# CY8C5888AXI_LP096 register map
File version: 0.1
CY8C58LP
Registers are 8-bit, read-write, no defined reset value unless marked. A register's access mark holds for its fields unless they carry their own. Offsets are from the block's base; lines under a group give offsets from that group; [hi:lo] are bit positions; {n}, {i} and the like mark numbered series; 'fields as' and 'values as' point back to an identical list; <NAME> marks a mode.

## Memory map
0x00000000 EN_B_PWM
0x00000000 EN_A_PWM
0x4000647D Motor_B
0x4000647F Motor_A

## Motor_B
Base 0x4000647D
0x00 Motor_B_CONTROL_REG

## EN_B_PWM
Base 0x00000000
0x4000642C EN_B_PWM_COMPARE_Reg 16-bit — UDB.D0 - Assigned Compare Value
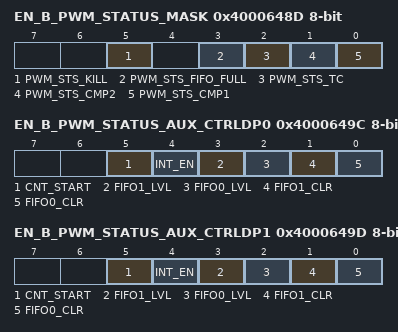
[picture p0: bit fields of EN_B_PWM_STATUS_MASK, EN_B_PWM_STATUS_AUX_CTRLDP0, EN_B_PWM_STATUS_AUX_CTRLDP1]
0x4000648D EN_B_PWM_STATUS_MASK — UDB Status bits Interrupt Mask Enable Register
  [5] PWM_STS_KILL ro — Enables the Interrupt on Kill
  [3] PWM_STS_FIFO_FULL ro — FIFO Full Status Mask
  [2] PWM_STS_TC ro — Enables the Interrupt on Terminal Count
  [1] PWM_STS_CMP2 ro — Enables the Interrupt on Compare 2
  [0] PWM_STS_CMP1 ro — Enables the Interrupt on Compare 1
0x4000649C EN_B_PWM_STATUS_AUX_CTRLDP0 — UDB Auxilliary Control Register
  [5] CNT_START — FIFO0 clear
    0=E_CNT_START0 (Disable counter); 1=E_CNT_START1 (Enable counter)
  [4] INT_EN
    0=E_INT_EN0 (Interrupt disabled); 1=E_INT_EN1 (Interrupt enabled)
  [3] FIFO1_LVL — FIFO level
    0=E_FIFO_LVL_0 (FIFO LVL: input mode: FIFO not full; output mode: FIFO not empty); 1=E_FIFO_LVL_1 (FIFO LVL: input mode: FIFO at least 1/2 empty; output mode: FIFO at least 1/2 full)
  [2] FIFO0_LVL — FIFO level
    values as FIFO1_LVL
  [1] FIFO1_CLR — FIFO1 clear
    0=E_FIFO_CLR_0 (Normal FIFO operation); 1=E_FIFO_CLR_1 (Clear FIFO state)
  [0] FIFO0_CLR — FIFO0 clear
    values as FIFO1_CLR
0x4000649D EN_B_PWM_STATUS_AUX_CTRLDP1 — UDB Auxilliary Control Register
  fields as EN_B_PWM_STATUS_AUX_CTRLDP0

## EN_A_PWM
Base 0x00000000
0x4000642E EN_A_PWM_COMPARE_Reg 16-bit — UDB.D0 - Assigned Compare Value
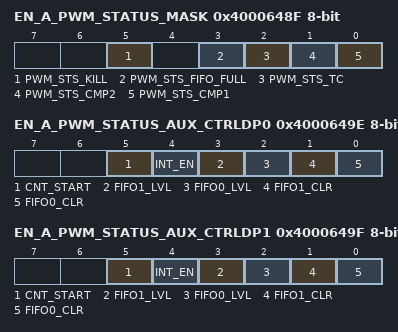
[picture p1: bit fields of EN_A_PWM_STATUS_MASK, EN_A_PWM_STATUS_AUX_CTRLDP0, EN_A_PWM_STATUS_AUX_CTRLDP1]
0x4000648F EN_A_PWM_STATUS_MASK — UDB Status bits Interrupt Mask Enable Register
  fields as EN_B_PWM.EN_B_PWM_STATUS_MASK
0x4000649E EN_A_PWM_STATUS_AUX_CTRLDP0 — UDB Auxilliary Control Register
  fields as EN_B_PWM.EN_B_PWM_STATUS_AUX_CTRLDP0
0x4000649F EN_A_PWM_STATUS_AUX_CTRLDP1 — UDB Auxilliary Control Register
  fields as EN_B_PWM.EN_B_PWM_STATUS_AUX_CTRLDP0

## Motor_A
Base 0x4000647F
Registers as Motor_B (with Motor_B read as Motor_A).
